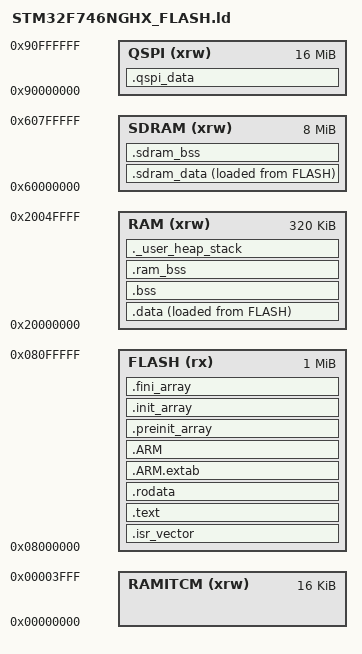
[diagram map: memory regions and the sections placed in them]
/**
 ******************************************************************************
 * @file      LinkerScript.ld
 * @author    Auto-generated by STM32CubeIDE
 *  Abstract    : Linker script for STM32F746G-DISCO Board embedding STM32F746NGHx Device from stm32f7 series
 *                      1024Kbytes FLASH
 *                      320Kbytes RAM
 *
 *            Set heap size, stack size and stack location according
 *            to application requirements.
 *
 *            Set memory bank area and size if external memory is used
 ******************************************************************************
 * @attention
 *
 * <h2><center>&copy; Copyright (c) 2020 STMicroelectronics.
 * All rights reserved.</center></h2>
 *
 * This software component is licensed by ST under BSD 3-Clause license,
 * the "License"; You may not use this file except in compliance with the
 * License. You may obtain a copy of the License at:
 *                        opensource.org/licenses/BSD-3-Clause
 *
 ******************************************************************************
 */

/* Entry Point */
ENTRY(Reset_Handler)

/* Highest address of the user mode stack */
_estack = ORIGIN(RAM) + LENGTH(RAM);	/* end of "RAM" Ram type memory */
/*_estack = ORIGIN(RAMITCM) + LENGTH(RAMITCM);	/* end of "RAM" Ram type memory */

_Min_Heap_Size = 0x600 ;	/* required amount of heap  */
_Min_Stack_Size = 0xB00 ;	/* required amount of stack */

/* Memories definition */
/* RAMITCM  (xrw)    : ORIGIN = 0x00000000,   LENGTH = 16K */
/* DTCM     (xrw)    : ORIGIN = 0x20000000,   LENGTH = 1536 */
/* SDRAM    (xrw)    : ORIGIN = 0xC0000000,   LENGTH = 8M */
MEMORY
{
  RAMITCM  (xrw)    : ORIGIN = 0x00000000,   LENGTH = 16K
  FLASH    (rx)     : ORIGIN = 0x08000000,   LENGTH = 1024K
  RAM      (xrw)    : ORIGIN = 0x20000000,   LENGTH = 320K
  SDRAM	   (xrw)	: ORIGIN = 0x60000000,	 LENGTH = 8M
  QSPI     (xrw)    : ORIGIN = 0x90000000,   LENGTH = 16M
}

/* Sections */
SECTIONS
{
  /* The startup code into "FLASH" Rom type memory */
  .isr_vector :
  {
    . = ALIGN(4);
    KEEP(*(.isr_vector)) /* Startup code */
    . = ALIGN(4);
  } >FLASH

  /* The program code and other data into "FLASH" Rom type memory */
  .text :
  {
    . = ALIGN(4);
    *(.text)           /* .text sections (code) */
    *(.text*)          /* .text* sections (code) */
    *(.glue_7)         /* glue arm to thumb code */
    *(.glue_7t)        /* glue thumb to arm code */
    *(.eh_frame)

    KEEP (*(.init))
    KEEP (*(.fini))

    . = ALIGN(4);
    _etext = .;        /* define a global symbols at end of code */
  } >FLASH
  
  /* used by the startup to initialize data */
/*  _siITCM = LOADADDR(.ITCMSection);

 .ITCMSection : {
   . = ALIGN(4);
   _sITCM = .;
   *(.ITCMSection)
   *(.ITCMSection*)
   . = ALIGN(4); 
   _eITCM = .;
   
 }>RAMITCM AT> FLASH	*/

  /* Constant data into "FLASH" Rom type memory */
  .rodata :
  {
    . = ALIGN(4);
    *(.rodata)         /* .rodata sections (constants, strings, etc.) */
    *(.rodata*)        /* .rodata* sections (constants, strings, etc.) */
    . = ALIGN(4);
  } >FLASH

  .ARM.extab   : {
    . = ALIGN(4);
    *(.ARM.extab* .gnu.linkonce.armextab.*)
    . = ALIGN(4);
  } >FLASH

  .ARM : {
    . = ALIGN(4);
    __exidx_start = .;
    *(.ARM.exidx*)
    __exidx_end = .;
    . = ALIGN(4);
  } >FLASH

  .preinit_array     :
  {
    . = ALIGN(4);
    PROVIDE_HIDDEN (__preinit_array_start = .);
    KEEP (*(.preinit_array*))
    PROVIDE_HIDDEN (__preinit_array_end = .);
    . = ALIGN(4);
  } >FLASH

  .init_array :
  {
    . = ALIGN(4);
    PROVIDE_HIDDEN (__init_array_start = .);
    KEEP (*(SORT(.init_array.*)))
    KEEP (*(.init_array*))
    PROVIDE_HIDDEN (__init_array_end = .);
    . = ALIGN(4);
  } >FLASH

  .fini_array :
  {
    . = ALIGN(4);
    PROVIDE_HIDDEN (__fini_array_start = .);
    KEEP (*(SORT(.fini_array.*)))
    KEEP (*(.fini_array*))
    PROVIDE_HIDDEN (__fini_array_end = .);
    . = ALIGN(4);
  } >FLASH

  .qspi_data :
  {
  	*(.qspi_data .qspi_data.*)
  	*(.gnu.linkonce.r.*)
  	. = ALIGN(0x4);
  } >QSPI
  
  /* Used by the startup to initialize data */
  _sidata = LOADADDR(.data);

  /* Initialized data sections into "RAM" Ram type memory */
  .data :
  {
    . = ALIGN(4);
    _sdata = .;        /* create a global symbol at data start */
    *(.data)           /* .data sections */
    *(.data*)          /* .data* sections */
    *(.RamFunc)        /* .RamFunc sections */
    *(.RamFunc*)       /* .RamFunc* sections */

    . = ALIGN(4);
    _edata = .;        /* define a global symbol at data end */

  } >RAM AT> FLASH /*>RAMITCM AT> FLASH /*>RAM AT> FLASH*/

  /* Used by the startup to initialize data */
  _sisdram_data = LOADADDR(.sdram_data);

  /* Initialized data sections into "RAM" Ram type memory */
  .sdram_data :
  {
    . = ALIGN(4);
    _ssdram_data = .;        /* create a global symbol at data start */
    *(.sdram_data)           /* .data sections */
    *(.sdram_data*)          /* .data* sections */
    *(.sdram_RamFunc)        /* .RamFunc sections */
    *(.sdram_RamFunc*)       /* .RamFunc* sections */

    . = ALIGN(4);
    _esdram_data = .;        /* define a global symbol at data end */

  } >SDRAM AT> FLASH

  /* Uninitialized data section into "RAMITCM" Ram type memory */
  /* Uninitialized data section into "RAM" Ram type memory */
  . = ALIGN(4);
  .bss :
  {
    /* This is used by the startup in order to initialize the .bss section */
    _sbss = .;         /* define a global symbol at bss start */
    __bss_start__ = _sbss;
    *(.bss)
    *(.bss*)
    *(COMMON)

    . = ALIGN(4);
    _ebss = .;         /* define a global symbol at bss end */
    __bss_end__ = _ebss;
  } >RAM /*>RAMITCM /*>RAM*/

  /* Uninitialized sdram data section into "RAM" Ram type memory */
  . = ALIGN(4);
  .ram_bss :
  {
    _sram_bss = .;
    __bss_start__ = _sram_bss;
    *(.ram_bss)
    *(.ram_bss*)

    . = ALIGN(4);
    _eram_bss = .;
    __bss_end__ = _eram_bss;
  } >RAM

  /* Uninitialized sdram data section into "SDRAM" Ram type memory */
  . = ALIGN(4);
  .sdram_bss :
  {
    _ssdram_bss = .;
    __bss_start__ = _ssdram_bss;
    *(.sdram_bss)
    *(.sdram_bss*)

    . = ALIGN(4);
    _esdram_bss = .;
    __bss_end__ = _esdram_bss;
  } >SDRAM

  /* User_heap_stack section, used to check that there is enough "RAM" Ram  type memory left */
  ._user_heap_stack :
  {
    . = ALIGN(8);
    PROVIDE ( end = . );
    PROVIDE ( _end = . );
    . = . + _Min_Heap_Size;
    . = . + _Min_Stack_Size;
    . = ALIGN(8);
  } >RAM /*>RAMITCM /*RAM*/ /*DTCM*/ /*RAM*/

  /* Remove information from the compiler libraries */
  /DISCARD/ :
  {
    libc.a ( * )
    libm.a ( * )
    libgcc.a ( * )
  }

  .ARM.attributes 0 : { *(.ARM.attributes) }
}
